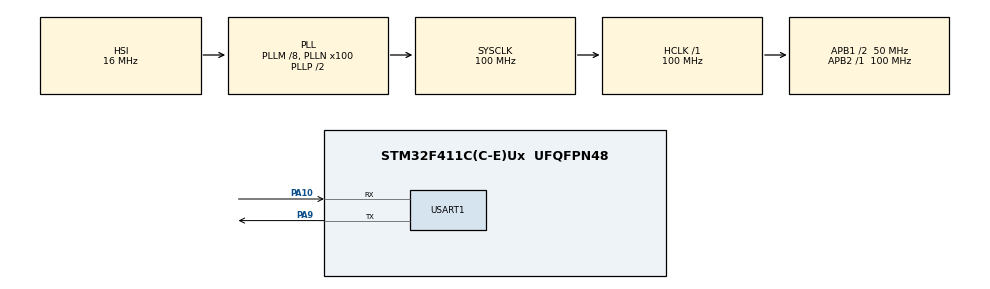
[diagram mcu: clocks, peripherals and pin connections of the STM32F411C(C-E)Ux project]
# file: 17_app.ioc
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Mcu.Family=STM32F4
Mcu.Name=STM32F411C(C-E)Ux
Mcu.Package=UFQFPN48
NVIC.PriorityGroup=NVIC_PRIORITYGROUP_4
PA10.Mode=Asynchronous
PA10.Signal=USART1_RX
PA13.Mode=Serial_Wire
PA13.Signal=SYS_JTMS-SWDIO
PA14.Mode=Serial_Wire
PA14.Signal=SYS_JTCK-SWCLK
PA9.Mode=Asynchronous
PA9.Signal=USART1_TX
PC14-OSC32_IN.Mode=LSE-External-Oscillator
PC14-OSC32_IN.Signal=RCC_OSC32_IN
PC15-OSC32_OUT.Mode=LSE-External-Oscillator
PC15-OSC32_OUT.Signal=RCC_OSC32_OUT
PH0\ -\ OSC_IN.Mode=HSE-External-Oscillator
PH0\ -\ OSC_IN.Signal=RCC_OSC_IN
PH1\ -\ OSC_OUT.Mode=HSE-External-Oscillator
PH1\ -\ OSC_OUT.Signal=RCC_OSC_OUT
ProjectManager.HeapSize=0x200
ProjectManager.StackSize=0x400
ProjectManager.TargetToolchain=MDK-ARM V5.32
RCC.48MHZClocksFreq_Value=50000000
RCC.AHBFreq_Value=100000000
RCC.APB1CLKDivider=RCC_HCLK_DIV2
RCC.APB1Freq_Value=50000000
RCC.APB1TimFreq_Value=100000000
RCC.APB2Freq_Value=100000000
RCC.APB2TimFreq_Value=100000000
RCC.CortexFreq_Value=100000000
RCC.HCLKFreq_Value=100000000
RCC.HSE_VALUE=25000000
RCC.HSI_VALUE=16000000
RCC.PLLM=8
RCC.PLLN=100
RCC.SYSCLKFreq_VALUE=100000000
RCC.SYSCLKSource=RCC_SYSCLKSOURCE_PLLCLK
RCC.VCOOutputFreq_Value=200000000
USART1.VirtualMode=VM_ASYNC
board=custom

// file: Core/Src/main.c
/* USER CODE BEGIN Header */
/**
  ******************************************************************************
  * @file           : main.c
  * @brief          : Main program body
  ******************************************************************************
  * @attention
  *
  * Copyright (c) 2026 STMicroelectronics.
  * All rights reserved.
  *
  * This software is licensed under terms that can be found in the LICENSE file
  * in the root directory of this software component.
  * If no LICENSE file comes with this software, it is provided AS-IS.
  *
  ******************************************************************************
  */
/* USER CODE END Header */
#include "main.h"
#include "usart.h"
#include "gpio.h"

/* USER CODE BEGIN Includes */
#include <stdio.h>
#include "elog.h"
/* USER CODE END Includes */

void SystemClock_Config(void);

/* USER CODE BEGIN PFP */
 #ifdef __GNUC__
     #define PUTCHAR_PROTOTYPE int _io_putchar(int ch)
 #else
     #define PUTCHAR_PROTOTYPE int fputc(int ch, FILE *f)
 #endif /* __GNUC__*/
/* USER CODE END PFP */

/* USER CODE BEGIN 0 */
 PUTCHAR_PROTOTYPE
 {
     HAL_UART_Transmit(&huart1, (uint8_t *)&ch,1,0xFFFF);
     return ch;
 }

 void Easylogger_Configuration(void)
{
	elog_init();
	elog_set_fmt(ELOG_LVL_ASSERT, ELOG_FMT_LVL);
	elog_set_fmt(ELOG_LVL_ERROR, ELOG_FMT_ALL);
	elog_set_fmt(ELOG_LVL_WARN, ELOG_FMT_LVL | ELOG_FMT_P_INFO);
	elog_set_fmt(ELOG_LVL_INFO, ELOG_FMT_ALL);
	elog_set_fmt(ELOG_LVL_DEBUG, ELOG_FMT_ALL);
	elog_set_fmt(ELOG_LVL_VERBOSE, ELOG_FMT_ALL);

	elog_start();
}

	void delay(volatile uint32_t count)
	{
		while (count--)
		{
			// 空循环，用于延时
		}
	}

	// 基于HCLK 100MHz 软件延时
	void delay_seconds(uint32_t seconds)
	{
		uint32_t count = 100000000;
		for (uint32_t i = 0; i < seconds; i++)
		{
			delay(count); // 软件延时
		}
	}
/* USER CODE END 0 */

int main(void)
{

  /* MCU Configuration--------------------------------------------------------*/

  /* Reset of all peripherals, Initializes the Flash interface and the Systick. */
		/* 向量表地址必须与 Bootloader 的 ApplicationAddress 一致 */
	SCB->VTOR = 0x08010000 ;
	__enable_irq();
	// HAL_DeInit();  // 删除！会复位外设，影响调试和系统稳定性
	SEGGER_RTT_Init();
	Easylogger_Configuration();
	log_i("jumped to app");
  RCC->AHB1ENR |= RCC_AHB1ENR_GPIOCEN;
  GPIOC->MODER = (GPIOC->MODER & ~(3u << 26)) | (1u << 26); // PC13 输出
  HAL_Init();

  /* Configure the system clock */
//  SystemClock_Config();

  /* Initialize all configured peripherals */
  MX_GPIO_Init();
  MX_USART1_UART_Init();
  /* USER CODE BEGIN 2 */
// 延时函数，依赖于HCLK频率

  /* USER CODE END 2 */

  /* Infinite loop */
  while (1)
  {
		log_i("hello world!");
		delay_seconds(1);
		GPIOC->ODR ^= (1u << 13);
		delay_seconds(1);

  }
  /* USER CODE END 3 */
}

void SystemClock_Config(void)
{
  RCC_OscInitTypeDef RCC_OscInitStruct = {0};
  RCC_ClkInitTypeDef RCC_ClkInitStruct = {0};

  /** Configure the main internal regulator output voltage
  */
  __HAL_RCC_PWR_CLK_ENABLE();
  __HAL_PWR_VOLTAGESCALING_CONFIG(PWR_REGULATOR_VOLTAGE_SCALE1);

  /** Initializes the RCC Oscillators according to the specified parameters
  * in the RCC_OscInitTypeDef structure.
  */
  RCC_OscInitStruct.OscillatorType = RCC_OSCILLATORTYPE_HSI;
  RCC_OscInitStruct.HSIState = RCC_HSI_ON;
  RCC_OscInitStruct.HSICalibrationValue = RCC_HSICALIBRATION_DEFAULT;
  RCC_OscInitStruct.PLL.PLLState = RCC_PLL_ON;
  RCC_OscInitStruct.PLL.PLLSource = RCC_PLLSOURCE_HSI;
  RCC_OscInitStruct.PLL.PLLM = 8;
  RCC_OscInitStruct.PLL.PLLN = 100;
  RCC_OscInitStruct.PLL.PLLP = RCC_PLLP_DIV2;
  RCC_OscInitStruct.PLL.PLLQ = 4;
  if (HAL_RCC_OscConfig(&RCC_OscInitStruct) != HAL_OK)
  {
    Error_Handler();
  }

  /** Initializes the CPU, AHB and APB buses clocks
  */
  RCC_ClkInitStruct.ClockType = RCC_CLOCKTYPE_HCLK|RCC_CLOCKTYPE_SYSCLK
                              |RCC_CLOCKTYPE_PCLK1|RCC_CLOCKTYPE_PCLK2;
  RCC_ClkInitStruct.SYSCLKSource = RCC_SYSCLKSOURCE_PLLCLK;
  RCC_ClkInitStruct.AHBCLKDivider = RCC_SYSCLK_DIV1;
  RCC_ClkInitStruct.APB1CLKDivider = RCC_HCLK_DIV2;
  RCC_ClkInitStruct.APB2CLKDivider = RCC_HCLK_DIV1;

  if (HAL_RCC_ClockConfig(&RCC_ClkInitStruct, FLASH_LATENCY_3) != HAL_OK)
  {
    Error_Handler();
  }
}

void Error_Handler(void)
{
  __disable_irq();
  while (1)
  {
  }
}
